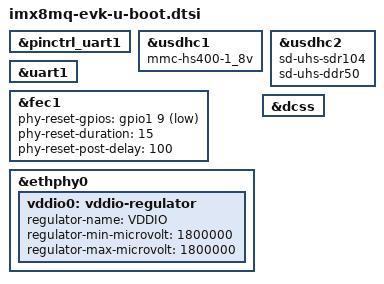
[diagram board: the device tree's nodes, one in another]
// SPDX-License-Identifier: (GPL-2.0 OR MIT)

#include "imx8mq-u-boot.dtsi"

&pinctrl_uart1 {
	u-boot,dm-spl;
};

&usdhc1 {
	mmc-hs400-1_8v;
};

&usdhc2 {
	sd-uhs-sdr104;
	sd-uhs-ddr50;
};

&uart1 {
	u-boot,dm-spl;
};

&fec1 {
	phy-reset-gpios = <&gpio1 9 GPIO_ACTIVE_LOW>;
	phy-reset-duration = <15>;
	phy-reset-post-delay = <100>;
};

&ethphy0 {
	vddio0: vddio-regulator {
		regulator-name = "VDDIO";
		regulator-min-microvolt = <1800000>;
		regulator-max-microvolt = <1800000>;
	};
};

&dcss {
	/delete-property/ assigned-clocks;
	/delete-property/ assigned-clock-parents;
	/delete-property/ assigned-clock-rates;
};
